# ADuCM363 register map
Vendor: Analog Devices Inc.; Series: ADuCM36x; File version: 0.1
CPU: CM3 r2p1, little endian, no MPU, no FPU, 3 interrupt priority bits
Registers are 16-bit, read-write, no defined reset value unless marked. A register's access mark holds for its fields unless they carry their own. Offsets are from the block's base; [hi:lo] are bit positions; {n}, {i} and the like mark numbered series; 'fields as' and 'values as' point back to an identical list.

## NVIC — Nested Vectored Interrupt Controller
Base 0xE000E000
0x04 ICTR 32-bit ro reset 0x1 (reset mask 0x0) — Shows the number of interrupt lines that the NVIC supports
  [3:0] INTLINESNUM range 0x00000000..0x0000000F — Total number of interrupt lines in groups of 32
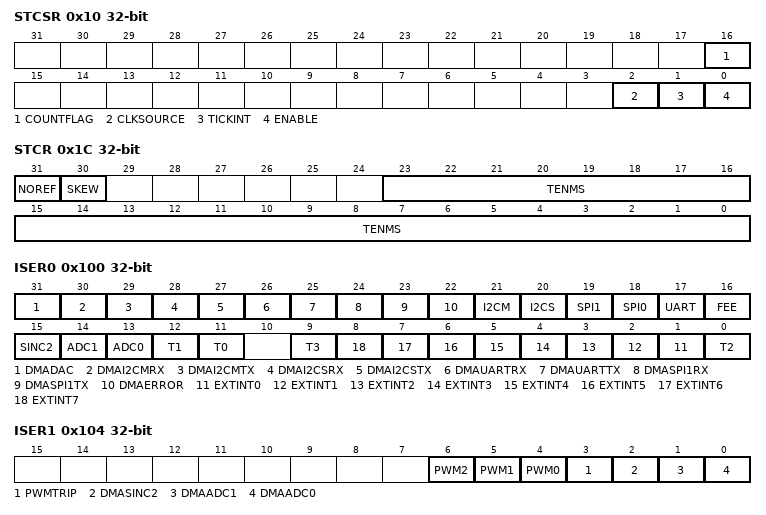
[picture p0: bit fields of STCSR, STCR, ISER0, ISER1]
0x10 STCSR 32-bit — SysTick Control and Status Register
  [all] fields
    0=DIS; 1=EN
  [16] COUNTFLAG — Returns 1 if timer counted to 0 since last time this register was read
  [2] CLKSOURCE — clock source used for SysTick
  [1] TICKINT — If 1, counting down to 0 will cause the SysTick exception to pended.
  [0] ENABLE — Enable bit
0x14 STRVR 32-bit — SysTick Reload Value Register
  [23:0] RELOAD range 0x00000000..0x00FFFFFF — Value to load into the Current Value register when the counter reaches 0
0x18 STCVR 32-bit — SysTick Current Value Register
  [31:0] CURRENT range 0x00000000..0xFFFFFFFF — Current counter value
0x1C STCR 32-bit ro — SysTick Calibration Value Register
  [31] NOREF — If reads as 1, the Reference clock is not provided
    0=DIS; 1=EN
  [30] SKEW — If reads as 1, the calibration value for 10ms is inexact
    0=DIS; 1=EN
  [23:0] TENMS range 0x00000000..0x00FFFFFF — An optional Reload value to be used for 10ms (100Hz) timing
0x100 ISER0 32-bit — IRQ0..31 Set_Enable
  [all] fields
    0=DIS; 1=EN
  [31] DMADAC
  [30] DMAI2CMRX
  [29] DMAI2CMTX
  [28] DMAI2CSRX
  [27] DMAI2CSTX
  [26] DMAUARTRX
  [25] DMAUARTTX
  [24] DMASPI1RX
  [23] DMASPI1TX
  [22] DMAERROR
  [21] I2CM
  [20] I2CS
  [19] SPI1
  [18] SPI0
  [17] UART
  [16] FEE
  [15] SINC2
  [14] ADC1
  [13] ADC0
  [12] T1
  [11] T0
  [9] T3
  [n+1] EXTINT{n} (n=0..7)
  [0] T2
0x104 ISER1 32-bit — IRQ32..63 Set_Enable
  [all] fields
    0=DIS; 1=EN
  [6] PWM2
  [5] PWM1
  [4] PWM0
  [3] PWMTRIP
  [2] DMASINC2
  [1] DMAADC1
  [0] DMAADC0
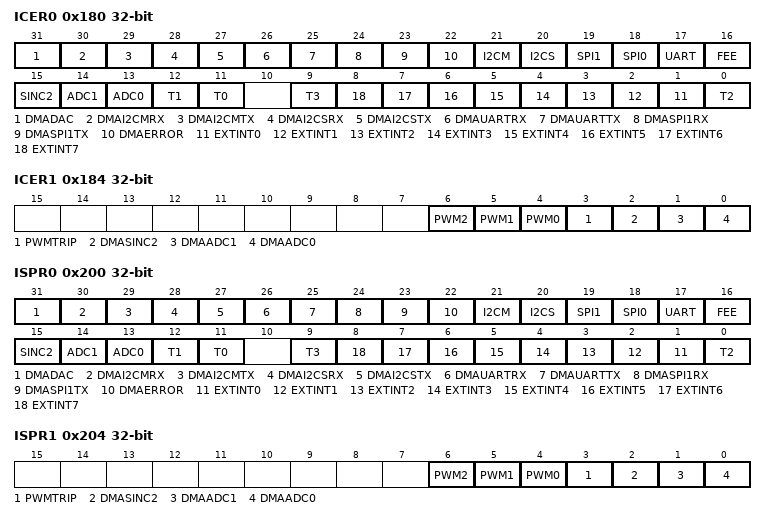
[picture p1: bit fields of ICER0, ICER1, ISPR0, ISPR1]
0x180 ICER0 32-bit — IRQ0..31 Clear_Enable
  fields as ISER0
0x184 ICER1 32-bit — IRQ32..63 Clear_Enable
  fields as ISER1
0x200 ISPR0 32-bit — IRQ0..31 Set_Pending
  fields as ISER0
0x204 ISPR1 32-bit — IRQ32..63 Set_Pending
  fields as ISER1
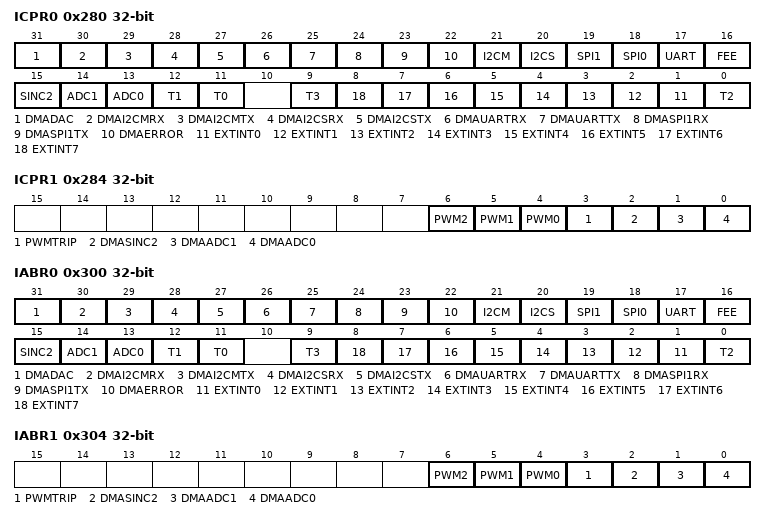
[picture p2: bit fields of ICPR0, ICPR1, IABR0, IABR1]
0x280 ICPR0 32-bit — IRQ0..31 Clear_Pending
  fields as ISER0
0x284 ICPR1 32-bit — IRQ32..63 Clear_Pending
  fields as ISER1
0x300 IABR0 32-bit — IRQ0..31 Active Bit
  fields as ISER0
0x304 IABR1 32-bit — IRQ32..63 Active Bit
  fields as ISER1
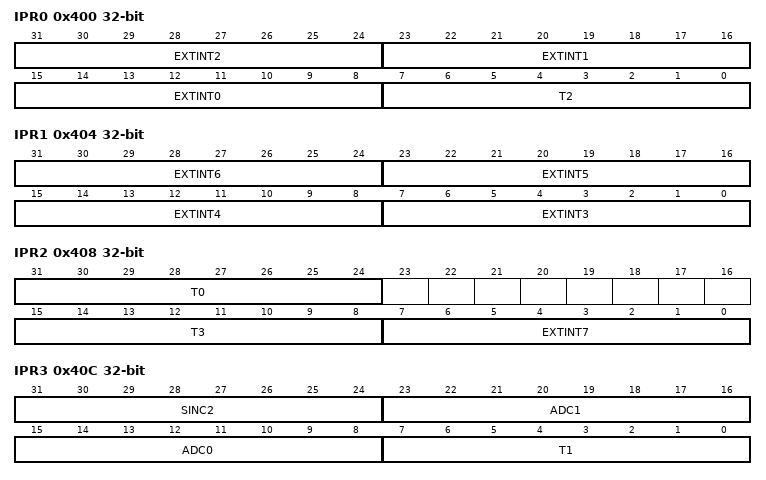
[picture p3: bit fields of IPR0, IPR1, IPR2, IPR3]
0x400 IPR0 32-bit — IRQ0..3 Priority
  [31:24] EXTINT2 range 0x00000000..0x000000FF
  [23:16] EXTINT1 range 0x00000000..0x000000FF
  [15:8] EXTINT0 range 0x00000000..0x000000FF — Priority of interrupt number 1
  [7:0] T2 range 0x00000000..0x000000FF — Priority of interrupt number 0
0x404 IPR1 32-bit — IRQ4..7 Priority
  [8n-17:8n-24] EXTINT{n} range 0x00000000..0x000000FF (n=3..6)
0x408 IPR2 32-bit — IRQ8..11 Priority
  [31:24] T0 range 0x00000000..0x000000FF, [15:8] T3 range 0x00000000..0x000000FF, [7:0] EXTINT7 range 0x00000000..0x000000FF
0x40C IPR3 32-bit — IRQ12..15 Priority
  [31:24] SINC2 range 0x00000000..0x000000FF, [23:16] ADC1 range 0x00000000..0x000000FF, [15:8] ADC0 range 0x00000000..0x000000FF, [7:0] T1 range 0x00000000..0x000000FF
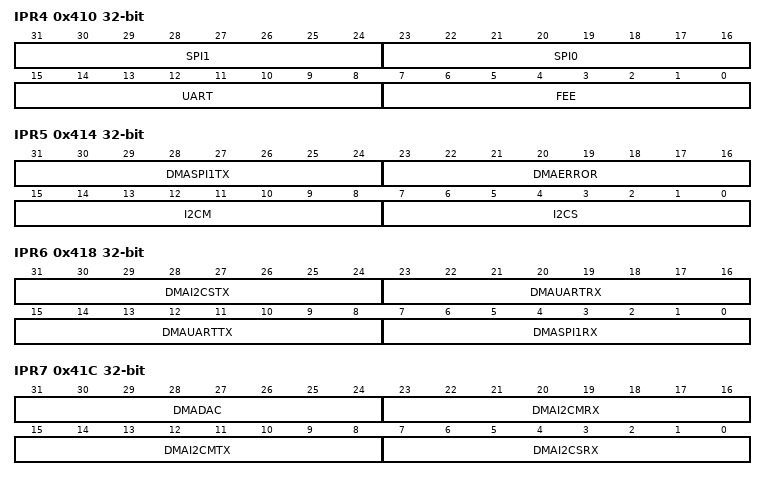
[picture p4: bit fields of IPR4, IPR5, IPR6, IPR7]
0x410 IPR4 32-bit — IRQ16..19 Priority
  [31:24] SPI1 range 0x00000000..0x000000FF, [23:16] SPI0 range 0x00000000..0x000000FF, [15:8] UART range 0x00000000..0x000000FF, [7:0] FEE range 0x00000000..0x000000FF
0x414 IPR5 32-bit — IRQ20..23 Priority
  [31:24] DMASPI1TX range 0x00000000..0x000000FF, [23:16] DMAERROR range 0x00000000..0x000000FF, [15:8] I2CM range 0x00000000..0x000000FF, [7:0] I2CS range 0x00000000..0x000000FF
0x418 IPR6 32-bit — IRQ24..27 Priority
  [31:24] DMAI2CSTX range 0x00000000..0x000000FF, [23:16] DMAUARTRX range 0x00000000..0x000000FF, [15:8] DMAUARTTX range 0x00000000..0x000000FF, [7:0] DMASPI1RX range 0x00000000..0x000000FF
0x41C IPR7 32-bit — IRQ28..31 Priority
  [31:24] DMADAC range 0x00000000..0x000000FF, [23:16] DMAI2CMRX range 0x00000000..0x000000FF, [15:8] DMAI2CMTX range 0x00000000..0x000000FF, [7:0] DMAI2CSRX range 0x00000000..0x000000FF
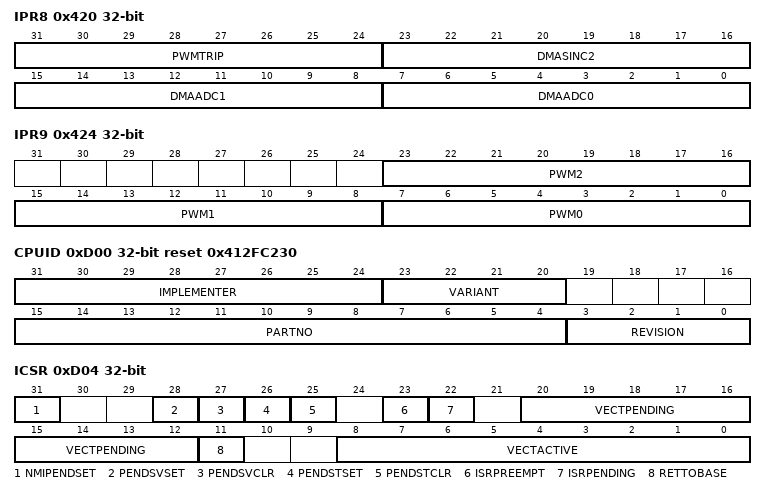
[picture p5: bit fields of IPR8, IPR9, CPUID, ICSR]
0x420 IPR8 32-bit — IRQ32..35 Priority
  [31:24] PWMTRIP range 0x00000000..0x000000FF, [23:16] DMASINC2 range 0x00000000..0x000000FF, [15:8] DMAADC1 range 0x00000000..0x000000FF, [7:0] DMAADC0 range 0x00000000..0x000000FF
0x424 IPR9 32-bit — IRQ36..39 Priority
  [23:16] PWM2 range 0x00000000..0x000000FF, [15:8] PWM1 range 0x00000000..0x000000FF, [7:0] PWM0 range 0x00000000..0x000000FF
0xD00 CPUID 32-bit ro reset 0x412FC230 (reset mask 0x0) — CPUID Base
  [31:24] IMPLEMENTER range 0x00000000..0x000000FF — Indicates implementor
  [23:20] VARIANT range 0x00000000..0x0000000F — Indicates processor revision
  [15:4] PARTNO range 0x00000000..0x00000FFF — Indicates part number
  [3:0] REVISION range 0x00000000..0x0000000F — Indicates patch release
0xD04 ICSR 32-bit — Interrupt Control and State Register
  [31] NMIPENDSET — Setting this bit will activate an NMI
    0=DIS; 1=EN
  [28] PENDSVSET — Set a pending PendSV interrupt
    0=DIS; 1=EN
  [27] PENDSVCLR — Clear a pending PendSV interrupt
    0=DIS; 1=EN
  [26] PENDSTSET — Set a pending SysTick. Reads back with current state
    0=DIS; 1=EN
  [25] PENDSTCLR — Clear a pending SysTick
    0=DIS; 1=EN
  [23] ISRPREEMPT — If set, a pending exception will be serviced on exit from the debug halt state
    0=DIS; 1=EN
  [22] ISRPENDING — Indicates if an external configurable is pending
    0=DIS; 1=EN
  [20:12] VECTPENDING range 0x00000000..0x000001FF — Indicates the exception number for the highest priority pending exception
  [11] RETTOBASE
    0=DIS; 1=EN
  [8:0] VECTACTIVE range 0x00000000..0x000001FF — Thread mode, or exception number
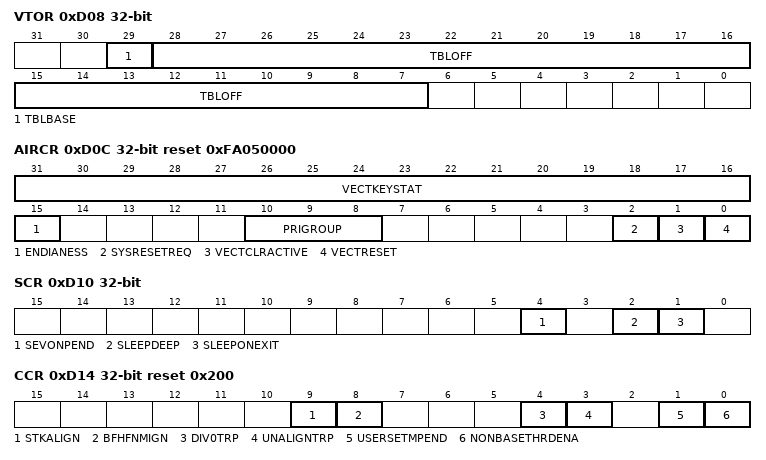
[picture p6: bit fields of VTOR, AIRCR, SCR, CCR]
0xD08 VTOR 32-bit — Vector Table Offset Register
  [29] TBLBASE
    0=DIS; 1=EN
  [28:7] TBLOFF range 0x00000000..0x003FFFFF
0xD0C AIRCR 32-bit reset 0xFA050000 (reset mask 0x0) — Application Interrupt and Reset Control Register
  [31:16] VECTKEYSTAT range 0x00000000..0x0000FFFF — Reads as 0xFA05
  [15] ENDIANESS — This bit is static or configured by a hardware input on reset
    0=DIS; 1=EN
  [10:8] PRIGROUP range 0x00000000..0x00000007 — Priority grouping position
  [2] SYSRESETREQ — System Reset Request
    0=DIS; 1=EN
  [1] VECTCLRACTIVE — Clears all active state information for fixed and configurable exceptions
    0=DIS; 1=EN
  [0] VECTRESET — Local system reset
    0=DIS; 1=EN
0xD10 SCR 32-bit — System Control Register
  [all] fields
    0=DIS; 1=EN
  [4] SEVONPEND
  [2] SLEEPDEEP — Sleep deep bit
  [1] SLEEPONEXIT — Sleep on exit when returning from handler mode to thread mode
0xD14 CCR 32-bit reset 0x200 (reset mask 0x0) — Configuration Control
  [all] fields
    0=DIS; 1=EN
  [9] STKALIGN
  [8] BFHFNMIGN
  [4] DIV0TRP
  [3] UNALIGNTRP
  [1] USERSETMPEND
  [0] NONBASETHRDENA
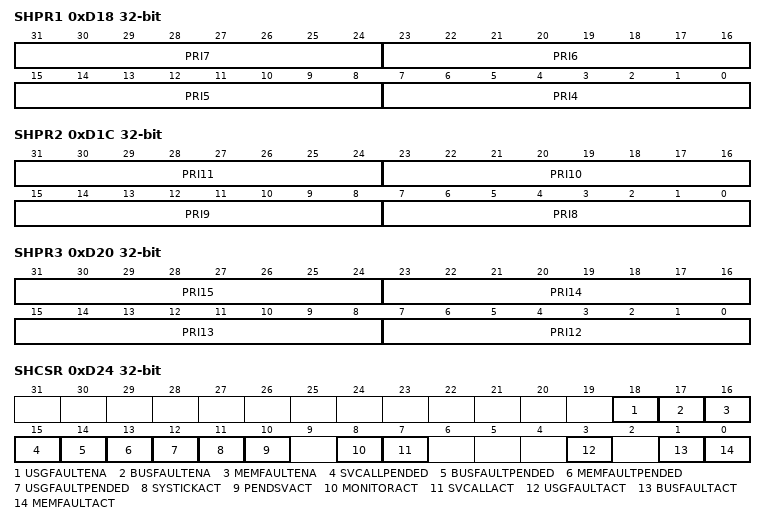
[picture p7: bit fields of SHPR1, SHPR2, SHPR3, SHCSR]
0xD18 SHPR1 32-bit — System Handler Priority Register 1
  [31:24] PRI7 range 0x00000000..0x000000FF — Priority of system handler 7 - reserved
  [23:16] PRI6 range 0x00000000..0x000000FF — Priority of system handler 6 - UsageFault
  [15:8] PRI5 range 0x00000000..0x000000FF — Priority of system handler 5 - BusFault
  [7:0] PRI4 range 0x00000000..0x000000FF — Priority of system handler 4 - MemManage
0xD1C SHPR2 32-bit — System Handler Priority Register 2
  [31:24] PRI11 range 0x00000000..0x000000FF — Priority of system handler 11 - SVCall
  [23:16] PRI10 range 0x00000000..0x000000FF — Priority of system handler 10 - reserved
  [15:8] PRI9 range 0x00000000..0x000000FF — Priority of system handler 9 - reserved
  [7:0] PRI8 range 0x00000000..0x000000FF — Priority of system handler 8 - reserved
0xD20 SHPR3 32-bit — System Handler Priority Register 3
  [31:24] PRI15 range 0x00000000..0x000000FF — Priority of system handler 15 - SysTick
  [23:16] PRI14 range 0x00000000..0x000000FF — Priority of system handler 14 - PendSV
  [15:8] PRI13 range 0x00000000..0x000000FF — Priority of system handler 13 - reserved
  [7:0] PRI12 range 0x00000000..0x000000FF — Priority of system handler 12 - DebugMonitor
0xD24 SHCSR 32-bit — System Handler Control and State
  [all] fields
    0=DIS; 1=EN
  [18] USGFAULTENA — Enable for UsageFault
  [17] BUSFAULTENA — Enable for BusFault.
  [16] MEMFAULTENA — Enable for MemManage fault.
  [15] SVCALLPENDED — Reads as 1 if SVCall is Pending
  [14] BUSFAULTPENDED — Reads as 1 if BusFault is Pending
  [13] MEMFAULTPENDED — Reads as 1 if MemManage is Pending
  [12] USGFAULTPENDED — Reads as 1 if UsageFault is Pending
  [11] SYSTICKACT — Reads as 1 if SysTick is Active
  [10] PENDSVACT — Reads as 1 if PendSV is Active
  [8] MONITORACT — Reads as 1 if the Monitor is Active
  [7] SVCALLACT — Reads as 1 if SVCall is Active
  [3] USGFAULTACT — Reads as 1 if UsageFault is Active.
  [1] BUSFAULTACT — Reads as 1 if BusFault is Active.
  [0] MEMFAULTACT — Reads as 1 if MemManage is Active
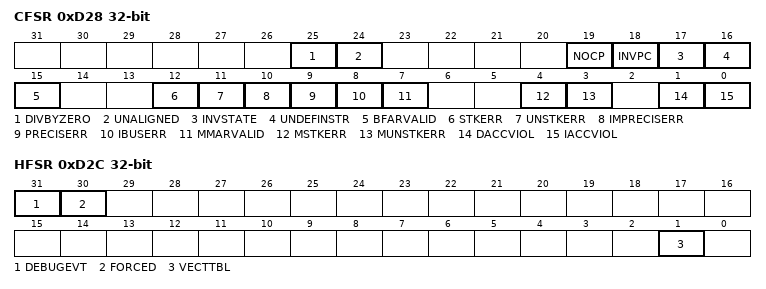
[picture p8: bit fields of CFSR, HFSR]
0xD28 CFSR 32-bit — Configurable Fault Status
  [all] fields
    0=DIS; 1=EN
  [25] DIVBYZERO — Divide by zero error
  [24] UNALIGNED — Unaligned access error
  [19] NOCP — Coprocessor access error
  [18] INVPC — Integrity check error on EXC_RETURN
  [17] INVSTATE — Invalid EPSR.T bit or illegal EPSR.IT bits for executing
  [16] UNDEFINSTR — Undefined instruction executed
  [15] BFARVALID — This bit is set if the BFAR register has valid contents
  [12] STKERR — This bit indicates a derived bus fault has occurred on exception entry
  [11] UNSTKERR — This bit indicates a derived bus fault has occurred on exception return
  [10] IMPRECISERR — Imprecise data access error
  [9] PRECISERR — Precise data access error. The BFAR is written with the faulting address
  [8] IBUSERR — This bit indicates a bus fault on an instruction prefetch
  [7] MMARVALID — This bit is set if the MMAR register has valid contents.
  [4] MSTKERR — A derived MemManage fault has occurred on exception entry
  [3] MUNSTKERR — A derived MemManage fault has occurred on exception return
  [1] DACCVIOL — Data access violation. The MMAR is set to the data address which the load store tried to access.
  [0] IACCVIOL — violation on an instruction fetch.
0xD2C HFSR 32-bit — Hard Fault Status
  [all] fields
    0=DIS; 1=EN
  [31] DEBUGEVT — Debug event, and the Debug Fault Status Register has been updated.
  [30] FORCED — Configurable fault cannot be activated due to priority or it was disabled. Priority escalated to a HardFault.
  [1] VECTTBL — Fault was due to vector table read on exception processing
0xD34 MMFAR 32-bit — Mem Manage Address
  [31:0] ADDRESS range 0x00000000..0xFFFFFFFF — Data address MPU faulted.
0xD38 BFAR 32-bit — Bus Fault Address
  [31:0] ADDRESS range 0x00000000..0xFFFFFFFF — Updated on precise data access faults
0xF00 STIR 32-bit wo — Software Trigger Interrupt Register
  [9:0] INTID range 0x00000000..0x000003FF — The value written in this field is the interrupt to be triggered.
